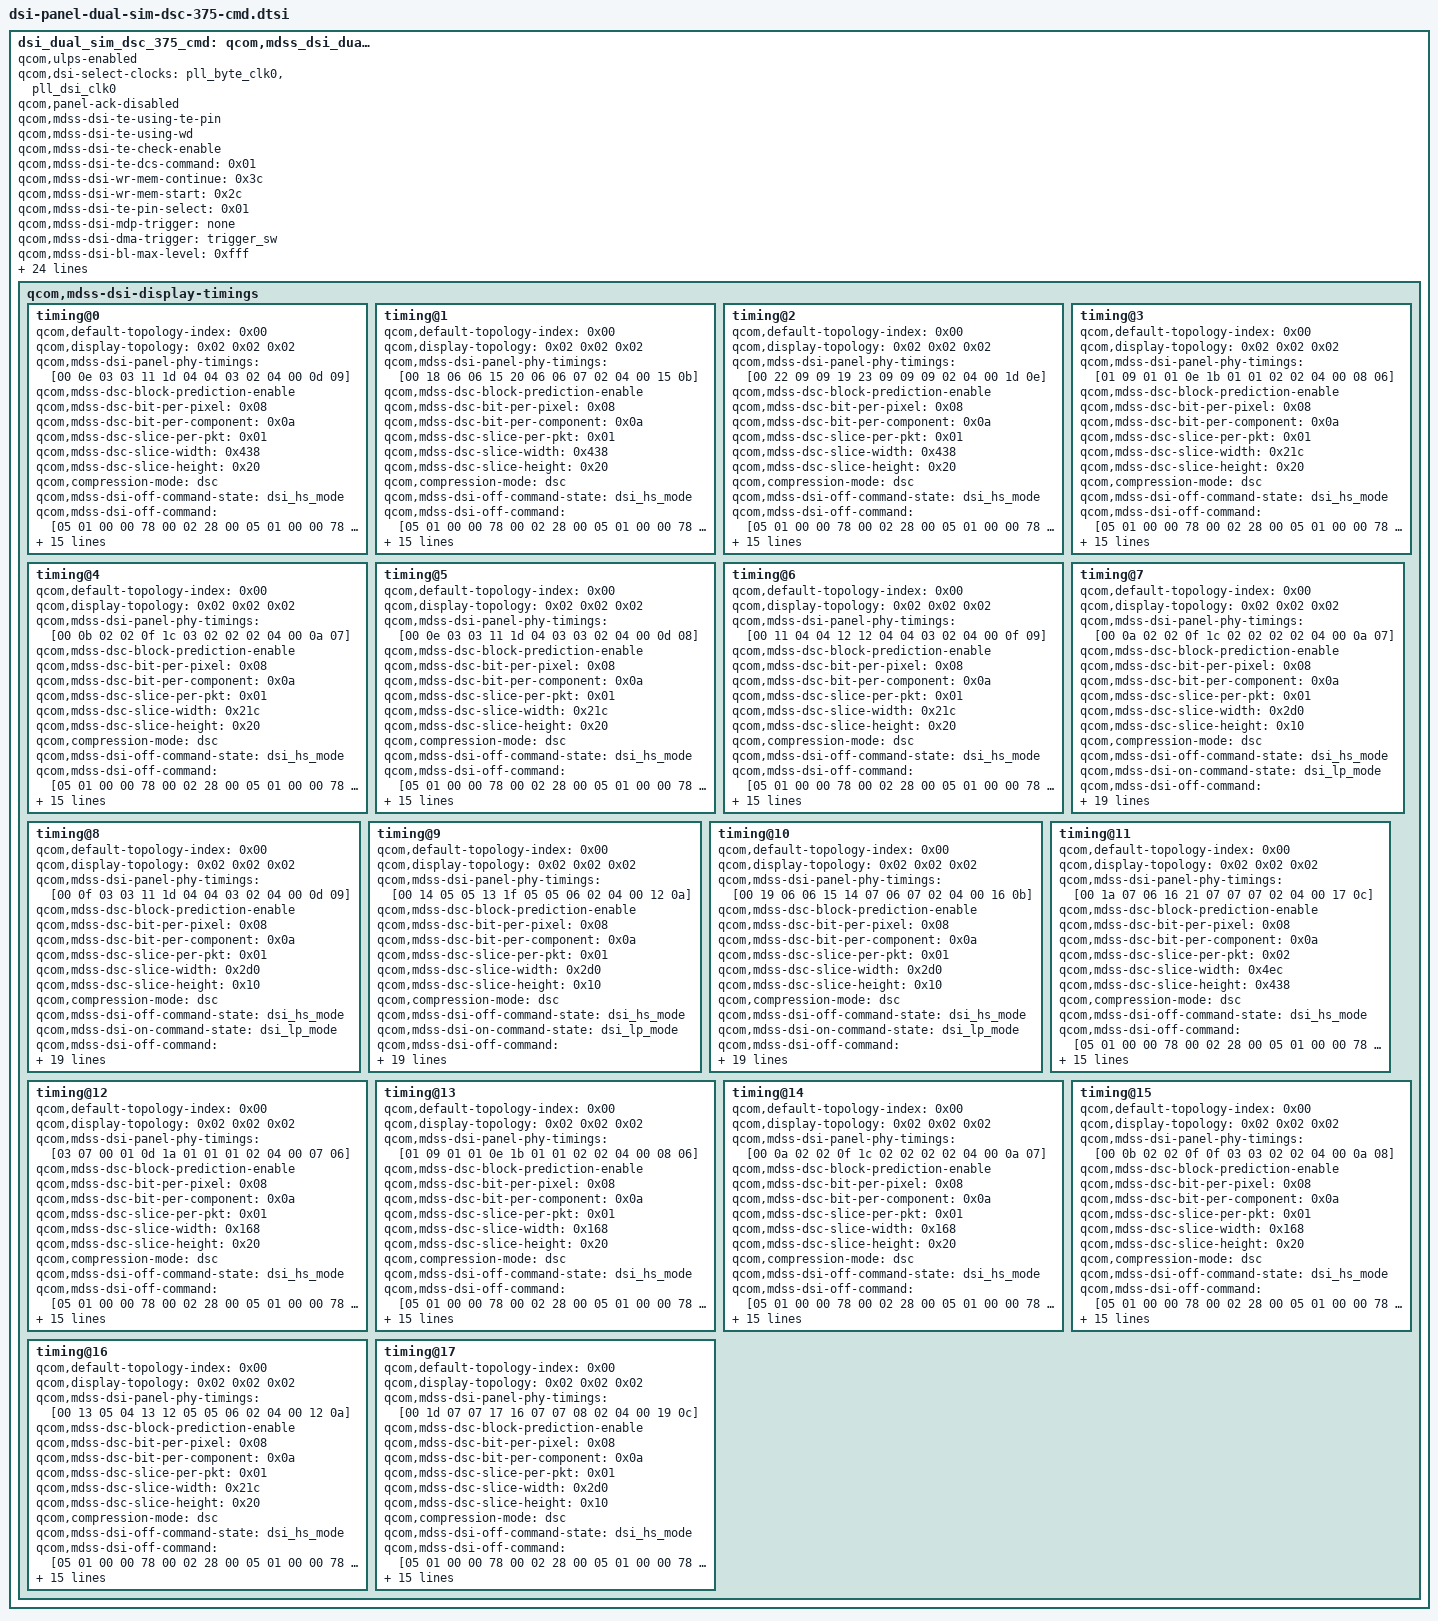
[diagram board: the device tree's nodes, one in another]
// SPDX-License-Identifier: BSD-3-Clause
/*
 * Copyright (c) 2023-2024 Qualcomm Innovation Center, Inc. All rights reserved.
 * Copyright (c) 2025 The LineageOS Project
 */

dsi_dual_sim_dsc_375_cmd: qcom,mdss_dsi_dual_sim_dsc_375_cmd {
	qcom,ulps-enabled;
	qcom,dsi-select-clocks = "pll_byte_clk0", "pll_dsi_clk0";
	qcom,panel-ack-disabled;
	qcom,mdss-dsi-te-using-te-pin;
	qcom,mdss-dsi-te-using-wd;
	qcom,mdss-dsi-te-check-enable;
	qcom,mdss-dsi-te-dcs-command = <0x01>;
	qcom,mdss-dsi-wr-mem-continue = <0x3c>;
	qcom,mdss-dsi-wr-mem-start = <0x2c>;
	qcom,mdss-dsi-te-pin-select = <0x01>;
	qcom,mdss-dsi-mdp-trigger = "none";
	qcom,mdss-dsi-dma-trigger = "trigger_sw";
	qcom,mdss-dsi-bl-max-level = <0xfff>;
	qcom,mdss-dsi-reset-sequence = <0x01 0x0a 0x00 0x0a 0x01 0x0a>;
	qcom,mdss-dsi-hor-line-idle = <0x00 0x28 0x100 0x28 0x78 0x80 0x78 0xf0 0x40>;
	qcom,mdss-dsi-lane-3-state;
	qcom,mdss-dsi-lane-2-state;
	qcom,mdss-dsi-lane-1-state;
	qcom,mdss-dsi-lane-0-state;
	qcom,cmd-sync-wait-broadcast;
	qcom,mdss-dsi-bllp-power-mode;
	qcom,mdss-dsi-bllp-eof-power-mode;
	qcom,mdss-dsi-traffic-mode = "non_burst_sync_event";
	qcom,mdss-dsi-border-color = <0x00>;
	qcom,mdss-dsi-underflow-color = <0xff>;
	qcom,mdss-dsi-color-order = "rgb_swap_rgb";
	qcom,mdss-dsi-bpp = <0x18>;
	qcom,mdss-dsi-stream = <0x00>;
	qcom,mdss-dsi-virtual-channel-id = <0x00>;
	qcom,dsi-phy-num = <0x00 0x01>;
	qcom,dsi-ctrl-num = <0x00 0x01>;
	qcom,mdss-dsi-panel-type = "dsi_cmd_mode";
	qcom,mdss-dsi-panel-name = "Sim dual cmd mode DSC 3.75:1 dsi panel";

	qcom,mdss-dsi-display-timings {

		timing@0 {
			qcom,default-topology-index = <0x00>;
			qcom,display-topology = <0x02 0x02 0x02>;
			qcom,mdss-dsi-panel-phy-timings = [00 0e 03 03 11 1d 04 04 03 02 04 00 0d 09];
			qcom,mdss-dsc-block-prediction-enable;
			qcom,mdss-dsc-bit-per-pixel = <0x08>;
			qcom,mdss-dsc-bit-per-component = <0x0a>;
			qcom,mdss-dsc-slice-per-pkt = <0x01>;
			qcom,mdss-dsc-slice-width = <0x438>;
			qcom,mdss-dsc-slice-height = <0x20>;
			qcom,compression-mode = "dsc";
			qcom,mdss-dsi-off-command-state = "dsi_hs_mode";
			qcom,mdss-dsi-off-command = [05 01 00 00 78 00 02 28 00 05 01 00 00 78 00 02 10 00];
			qcom,mdss-dsi-on-command-state = "dsi_lp_mode";
			qcom,mdss-dsi-on-command = [39 01 00 00 00 00 11 91 09 20 00 20 02 00 03 1c 04 21 00 0f 03 19 01 97 39 01 00 00 00 00 03 92 10 f0 15 01 00 00 00 00 02 90 03 15 01 00 00 00 00 02 03 01 39 01 00 00 00 00 06 f0 55 aa 52 08 04 15 01 00 00 00 00 02 c0 03 39 01 00 00 00 00 06 f0 55 aa 52 08 07 15 01 00 00 00 00 02 ef 01 39 01 00 00 00 00 06 f0 55 aa 52 08 00 15 01 00 00 00 00 02 b4 01 15 01 00 00 00 00 02 35 00 39 01 00 00 00 00 06 f0 55 aa 52 08 01 39 01 00 00 00 00 05 ff aa 55 a5 80 15 01 00 00 00 00 02 6f 01 15 01 00 00 00 00 02 f3 10 39 01 00 00 00 00 05 ff aa 55 a5 00 05 01 00 00 f0 00 01 00];
			qcom,mdss-dsi-panel-framerate = <0x1e>;
			qcom,mdss-dsi-h-sync-pulse = <0x00>;
			qcom,mdss-dsi-v-pulse-width = <0x01>;
			qcom,mdss-dsi-v-front-porch = <0x08>;
			qcom,mdss-dsi-v-back-porch = <0x07>;
			qcom,mdss-dsi-h-sync-skew = <0x00>;
			qcom,mdss-dsi-h-pulse-width = <0x04>;
			qcom,mdss-dsi-h-back-porch = <0x64>;
			qcom,mdss-dsi-h-front-porch = <0x1e>;
			qcom,mdss-dsi-panel-height = <0xf00>;
			qcom,mdss-dsi-panel-width = <0x438>;
			cell-index = <0x00>;
		};

		timing@1 {
			qcom,default-topology-index = <0x00>;
			qcom,display-topology = <0x02 0x02 0x02>;
			qcom,mdss-dsi-panel-phy-timings = [00 18 06 06 15 20 06 06 07 02 04 00 15 0b];
			qcom,mdss-dsc-block-prediction-enable;
			qcom,mdss-dsc-bit-per-pixel = <0x08>;
			qcom,mdss-dsc-bit-per-component = <0x0a>;
			qcom,mdss-dsc-slice-per-pkt = <0x01>;
			qcom,mdss-dsc-slice-width = <0x438>;
			qcom,mdss-dsc-slice-height = <0x20>;
			qcom,compression-mode = "dsc";
			qcom,mdss-dsi-off-command-state = "dsi_hs_mode";
			qcom,mdss-dsi-off-command = [05 01 00 00 78 00 02 28 00 05 01 00 00 78 00 02 10 00];
			qcom,mdss-dsi-on-command-state = "dsi_lp_mode";
			qcom,mdss-dsi-on-command = [39 01 00 00 00 00 11 91 09 20 00 20 02 00 03 1c 04 21 00 0f 03 19 01 97 39 01 00 00 00 00 03 92 10 f0 15 01 00 00 00 00 02 90 03 15 01 00 00 00 00 02 03 01 39 01 00 00 00 00 06 f0 55 aa 52 08 04 15 01 00 00 00 00 02 c0 03 39 01 00 00 00 00 06 f0 55 aa 52 08 07 15 01 00 00 00 00 02 ef 01 39 01 00 00 00 00 06 f0 55 aa 52 08 00 15 01 00 00 00 00 02 b4 01 15 01 00 00 00 00 02 35 00 39 01 00 00 00 00 06 f0 55 aa 52 08 01 39 01 00 00 00 00 05 ff aa 55 a5 80 15 01 00 00 00 00 02 6f 01 15 01 00 00 00 00 02 f3 10 39 01 00 00 00 00 05 ff aa 55 a5 00 05 01 00 00 f0 00 01 00];
			qcom,mdss-dsi-panel-framerate = <0x3c>;
			qcom,mdss-dsi-h-sync-pulse = <0x00>;
			qcom,mdss-dsi-v-pulse-width = <0x01>;
			qcom,mdss-dsi-v-front-porch = <0x08>;
			qcom,mdss-dsi-v-back-porch = <0x07>;
			qcom,mdss-dsi-h-sync-skew = <0x00>;
			qcom,mdss-dsi-h-pulse-width = <0x04>;
			qcom,mdss-dsi-h-back-porch = <0x64>;
			qcom,mdss-dsi-h-front-porch = <0x1e>;
			qcom,mdss-dsi-panel-height = <0xf00>;
			qcom,mdss-dsi-panel-width = <0x438>;
			cell-index = <0x01>;
		};

		timing@2 {
			qcom,default-topology-index = <0x00>;
			qcom,display-topology = <0x02 0x02 0x02>;
			qcom,mdss-dsi-panel-phy-timings = [00 22 09 09 19 23 09 09 09 02 04 00 1d 0e];
			qcom,mdss-dsc-block-prediction-enable;
			qcom,mdss-dsc-bit-per-pixel = <0x08>;
			qcom,mdss-dsc-bit-per-component = <0x0a>;
			qcom,mdss-dsc-slice-per-pkt = <0x01>;
			qcom,mdss-dsc-slice-width = <0x438>;
			qcom,mdss-dsc-slice-height = <0x20>;
			qcom,compression-mode = "dsc";
			qcom,mdss-dsi-off-command-state = "dsi_hs_mode";
			qcom,mdss-dsi-off-command = [05 01 00 00 78 00 02 28 00 05 01 00 00 78 00 02 10 00];
			qcom,mdss-dsi-on-command-state = "dsi_lp_mode";
			qcom,mdss-dsi-on-command = [39 01 00 00 00 00 11 91 09 20 00 20 02 00 03 1c 04 21 00 0f 03 19 01 97 39 01 00 00 00 00 03 92 10 f0 15 01 00 00 00 00 02 90 03 15 01 00 00 00 00 02 03 01 39 01 00 00 00 00 06 f0 55 aa 52 08 04 15 01 00 00 00 00 02 c0 03 39 01 00 00 00 00 06 f0 55 aa 52 08 07 15 01 00 00 00 00 02 ef 01 39 01 00 00 00 00 06 f0 55 aa 52 08 00 15 01 00 00 00 00 02 b4 01 15 01 00 00 00 00 02 35 00 39 01 00 00 00 00 06 f0 55 aa 52 08 01 39 01 00 00 00 00 05 ff aa 55 a5 80 15 01 00 00 00 00 02 6f 01 15 01 00 00 00 00 02 f3 10 39 01 00 00 00 00 05 ff aa 55 a5 00 05 01 00 00 f0 00 01 00];
			qcom,mdss-dsi-panel-framerate = <0x5a>;
			qcom,mdss-dsi-h-sync-pulse = <0x00>;
			qcom,mdss-dsi-v-pulse-width = <0x01>;
			qcom,mdss-dsi-v-front-porch = <0x08>;
			qcom,mdss-dsi-v-back-porch = <0x07>;
			qcom,mdss-dsi-h-sync-skew = <0x00>;
			qcom,mdss-dsi-h-pulse-width = <0x04>;
			qcom,mdss-dsi-h-back-porch = <0x64>;
			qcom,mdss-dsi-h-front-porch = <0x1e>;
			qcom,mdss-dsi-panel-height = <0xf00>;
			qcom,mdss-dsi-panel-width = <0x438>;
			cell-index = <0x02>;
		};

		timing@3 {
			qcom,default-topology-index = <0x00>;
			qcom,display-topology = <0x02 0x02 0x02>;
			qcom,mdss-dsi-panel-phy-timings = [01 09 01 01 0e 1b 01 01 02 02 04 00 08 06];
			qcom,mdss-dsc-block-prediction-enable;
			qcom,mdss-dsc-bit-per-pixel = <0x08>;
			qcom,mdss-dsc-bit-per-component = <0x0a>;
			qcom,mdss-dsc-slice-per-pkt = <0x01>;
			qcom,mdss-dsc-slice-width = <0x21c>;
			qcom,mdss-dsc-slice-height = <0x20>;
			qcom,compression-mode = "dsc";
			qcom,mdss-dsi-off-command-state = "dsi_hs_mode";
			qcom,mdss-dsi-off-command = [05 01 00 00 78 00 02 28 00 05 01 00 00 78 00 02 10 00];
			qcom,mdss-dsi-on-command-state = "dsi_lp_mode";
			qcom,mdss-dsi-on-command = [39 01 00 00 00 00 11 91 09 20 00 20 02 00 03 1c 04 21 00 0f 03 19 01 97 39 01 00 00 00 00 03 92 10 f0 15 01 00 00 00 00 02 90 03 15 01 00 00 00 00 02 03 01 39 01 00 00 00 00 06 f0 55 aa 52 08 04 15 01 00 00 00 00 02 c0 03 39 01 00 00 00 00 06 f0 55 aa 52 08 07 15 01 00 00 00 00 02 ef 01 39 01 00 00 00 00 06 f0 55 aa 52 08 00 15 01 00 00 00 00 02 b4 01 15 01 00 00 00 00 02 35 00 39 01 00 00 00 00 06 f0 55 aa 52 08 01 39 01 00 00 00 00 05 ff aa 55 a5 80 15 01 00 00 00 00 02 6f 01 15 01 00 00 00 00 02 f3 10 39 01 00 00 00 00 05 ff aa 55 a5 00 05 01 00 00 f0 00 01 00];
			qcom,mdss-dsi-panel-framerate = <0x1e>;
			qcom,mdss-dsi-h-sync-pulse = <0x00>;
			qcom,mdss-dsi-v-pulse-width = <0x01>;
			qcom,mdss-dsi-v-front-porch = <0x08>;
			qcom,mdss-dsi-v-back-porch = <0x07>;
			qcom,mdss-dsi-h-sync-skew = <0x00>;
			qcom,mdss-dsi-h-pulse-width = <0x04>;
			qcom,mdss-dsi-h-back-porch = <0x64>;
			qcom,mdss-dsi-h-front-porch = <0x1e>;
			qcom,mdss-dsi-panel-height = <0x780>;
			qcom,mdss-dsi-panel-width = <0x21c>;
			cell-index = <0x04>;
		};

		timing@4 {
			qcom,default-topology-index = <0x00>;
			qcom,display-topology = <0x02 0x02 0x02>;
			qcom,mdss-dsi-panel-phy-timings = [00 0b 02 02 0f 1c 03 02 02 02 04 00 0a 07];
			qcom,mdss-dsc-block-prediction-enable;
			qcom,mdss-dsc-bit-per-pixel = <0x08>;
			qcom,mdss-dsc-bit-per-component = <0x0a>;
			qcom,mdss-dsc-slice-per-pkt = <0x01>;
			qcom,mdss-dsc-slice-width = <0x21c>;
			qcom,mdss-dsc-slice-height = <0x20>;
			qcom,compression-mode = "dsc";
			qcom,mdss-dsi-off-command-state = "dsi_hs_mode";
			qcom,mdss-dsi-off-command = [05 01 00 00 78 00 02 28 00 05 01 00 00 78 00 02 10 00];
			qcom,mdss-dsi-on-command-state = "dsi_lp_mode";
			qcom,mdss-dsi-on-command = [39 01 00 00 00 00 11 91 09 20 00 20 02 00 03 1c 04 21 00 0f 03 19 01 97 39 01 00 00 00 00 03 92 10 f0 15 01 00 00 00 00 02 90 03 15 01 00 00 00 00 02 03 01 39 01 00 00 00 00 06 f0 55 aa 52 08 04 15 01 00 00 00 00 02 c0 03 39 01 00 00 00 00 06 f0 55 aa 52 08 07 15 01 00 00 00 00 02 ef 01 39 01 00 00 00 00 06 f0 55 aa 52 08 00 15 01 00 00 00 00 02 b4 01 15 01 00 00 00 00 02 35 00 39 01 00 00 00 00 06 f0 55 aa 52 08 01 39 01 00 00 00 00 05 ff aa 55 a5 80 15 01 00 00 00 00 02 6f 01 15 01 00 00 00 00 02 f3 10 39 01 00 00 00 00 05 ff aa 55 a5 00 05 01 00 00 f0 00 01 00];
			qcom,mdss-dsi-panel-framerate = <0x3c>;
			qcom,mdss-dsi-h-sync-pulse = <0x00>;
			qcom,mdss-dsi-v-pulse-width = <0x01>;
			qcom,mdss-dsi-v-front-porch = <0x08>;
			qcom,mdss-dsi-v-back-porch = <0x07>;
			qcom,mdss-dsi-h-sync-skew = <0x00>;
			qcom,mdss-dsi-h-pulse-width = <0x04>;
			qcom,mdss-dsi-h-back-porch = <0x64>;
			qcom,mdss-dsi-h-front-porch = <0x1e>;
			qcom,mdss-dsi-panel-height = <0x780>;
			qcom,mdss-dsi-panel-width = <0x21c>;
			cell-index = <0x05>;
		};

		timing@5 {
			qcom,default-topology-index = <0x00>;
			qcom,display-topology = <0x02 0x02 0x02>;
			qcom,mdss-dsi-panel-phy-timings = [00 0e 03 03 11 1d 04 03 03 02 04 00 0d 08];
			qcom,mdss-dsc-block-prediction-enable;
			qcom,mdss-dsc-bit-per-pixel = <0x08>;
			qcom,mdss-dsc-bit-per-component = <0x0a>;
			qcom,mdss-dsc-slice-per-pkt = <0x01>;
			qcom,mdss-dsc-slice-width = <0x21c>;
			qcom,mdss-dsc-slice-height = <0x20>;
			qcom,compression-mode = "dsc";
			qcom,mdss-dsi-off-command-state = "dsi_hs_mode";
			qcom,mdss-dsi-off-command = [05 01 00 00 78 00 02 28 00 05 01 00 00 78 00 02 10 00];
			qcom,mdss-dsi-on-command-state = "dsi_lp_mode";
			qcom,mdss-dsi-on-command = [39 01 00 00 00 00 11 91 09 20 00 20 02 00 03 1c 04 21 00 0f 03 19 01 97 39 01 00 00 00 00 03 92 10 f0 15 01 00 00 00 00 02 90 03 15 01 00 00 00 00 02 03 01 39 01 00 00 00 00 06 f0 55 aa 52 08 04 15 01 00 00 00 00 02 c0 03 39 01 00 00 00 00 06 f0 55 aa 52 08 07 15 01 00 00 00 00 02 ef 01 39 01 00 00 00 00 06 f0 55 aa 52 08 00 15 01 00 00 00 00 02 b4 01 15 01 00 00 00 00 02 35 00 39 01 00 00 00 00 06 f0 55 aa 52 08 01 39 01 00 00 00 00 05 ff aa 55 a5 80 15 01 00 00 00 00 02 6f 01 15 01 00 00 00 00 02 f3 10 39 01 00 00 00 00 05 ff aa 55 a5 00 05 01 00 00 f0 00 01 00];
			qcom,mdss-dsi-panel-framerate = <0x5a>;
			qcom,mdss-dsi-h-sync-pulse = <0x00>;
			qcom,mdss-dsi-v-pulse-width = <0x01>;
			qcom,mdss-dsi-v-front-porch = <0x08>;
			qcom,mdss-dsi-v-back-porch = <0x07>;
			qcom,mdss-dsi-h-sync-skew = <0x00>;
			qcom,mdss-dsi-h-pulse-width = <0x04>;
			qcom,mdss-dsi-h-back-porch = <0x64>;
			qcom,mdss-dsi-h-front-porch = <0x1e>;
			qcom,mdss-dsi-panel-height = <0x780>;
			qcom,mdss-dsi-panel-width = <0x21c>;
			cell-index = <0x06>;
		};

		timing@6 {
			qcom,default-topology-index = <0x00>;
			qcom,display-topology = <0x02 0x02 0x02>;
			qcom,mdss-dsi-panel-phy-timings = [00 11 04 04 12 12 04 04 03 02 04 00 0f 09];
			qcom,mdss-dsc-block-prediction-enable;
			qcom,mdss-dsc-bit-per-pixel = <0x08>;
			qcom,mdss-dsc-bit-per-component = <0x0a>;
			qcom,mdss-dsc-slice-per-pkt = <0x01>;
			qcom,mdss-dsc-slice-width = <0x21c>;
			qcom,mdss-dsc-slice-height = <0x20>;
			qcom,compression-mode = "dsc";
			qcom,mdss-dsi-off-command-state = "dsi_hs_mode";
			qcom,mdss-dsi-off-command = [05 01 00 00 78 00 02 28 00 05 01 00 00 78 00 02 10 00];
			qcom,mdss-dsi-on-command-state = "dsi_lp_mode";
			qcom,mdss-dsi-on-command = [39 01 00 00 00 00 11 91 09 20 00 20 02 00 03 1c 04 21 00 0f 03 19 01 97 39 01 00 00 00 00 03 92 10 f0 15 01 00 00 00 00 02 90 03 15 01 00 00 00 00 02 03 01 39 01 00 00 00 00 06 f0 55 aa 52 08 04 15 01 00 00 00 00 02 c0 03 39 01 00 00 00 00 06 f0 55 aa 52 08 07 15 01 00 00 00 00 02 ef 01 39 01 00 00 00 00 06 f0 55 aa 52 08 00 15 01 00 00 00 00 02 b4 01 15 01 00 00 00 00 02 35 00 39 01 00 00 00 00 06 f0 55 aa 52 08 01 39 01 00 00 00 00 05 ff aa 55 a5 80 15 01 00 00 00 00 02 6f 01 15 01 00 00 00 00 02 f3 10 39 01 00 00 00 00 05 ff aa 55 a5 00 05 01 00 00 f0 00 01 00];
			qcom,mdss-dsi-panel-framerate = <0x78>;
			qcom,mdss-dsi-h-sync-pulse = <0x00>;
			qcom,mdss-dsi-v-pulse-width = <0x01>;
			qcom,mdss-dsi-v-front-porch = <0x08>;
			qcom,mdss-dsi-v-back-porch = <0x07>;
			qcom,mdss-dsi-h-sync-skew = <0x00>;
			qcom,mdss-dsi-h-pulse-width = <0x04>;
			qcom,mdss-dsi-h-back-porch = <0x64>;
			qcom,mdss-dsi-h-front-porch = <0x1e>;
			qcom,mdss-dsi-panel-height = <0x780>;
			qcom,mdss-dsi-panel-width = <0x21c>;
			cell-index = <0x07>;
		};

		timing@7 {
			qcom,default-topology-index = <0x00>;
			qcom,display-topology = <0x02 0x02 0x02>;
			qcom,mdss-dsi-panel-phy-timings = [00 0a 02 02 0f 1c 02 02 02 02 04 00 0a 07];
			qcom,mdss-dsc-block-prediction-enable;
			qcom,mdss-dsc-bit-per-pixel = <0x08>;
			qcom,mdss-dsc-bit-per-component = <0x0a>;
			qcom,mdss-dsc-slice-per-pkt = <0x01>;
			qcom,mdss-dsc-slice-width = <0x2d0>;
			qcom,mdss-dsc-slice-height = <0x10>;
			qcom,compression-mode = "dsc";
			qcom,mdss-dsi-off-command-state = "dsi_hs_mode";
			qcom,mdss-dsi-on-command-state = "dsi_lp_mode";
			qcom,mdss-dsi-off-command = [05 01 00 00 78 00 02 28 00 05 01 00 00 78 00 02 10 00];
			qcom,mdss-dsi-on-command = [15 01 00 00 00 00 02 ff 20 15 01 00 00 00 00 02 fb 01 15 01 00 00 00 00 02 00 01 15 01 00 00 00 00 02 01 55 15 01 00 00 00 00 02 02 45 15 01 00 00 00 00 02 05 40 15 01 00 00 00 00 02 06 19 15 01 00 00 00 00 02 07 1e 15 01 00 00 00 00 02 0b 73 15 01 00 00 00 00 02 0c 73 15 01 00 00 00 00 02 0e b0 15 01 00 00 00 00 02 0f ae 15 01 00 00 00 00 02 11 b8 15 01 00 00 00 00 02 13 00 15 01 00 00 00 00 02 58 80 15 01 00 00 00 00 02 59 01 15 01 00 00 00 00 02 5a 00 15 01 00 00 00 00 02 5b 01 15 01 00 00 00 00 02 5c 80 15 01 00 00 00 00 02 5d 81 15 01 00 00 00 00 02 5e 00 15 01 00 00 00 00 02 5f 01 15 01 00 00 00 00 02 72 31 15 01 00 00 00 00 02 68 03 15 01 00 00 00 00 02 ff 24 15 01 00 00 00 00 02 fb 01 15 01 00 00 00 00 02 00 1c 15 01 00 00 00 00 02 01 0b 15 01 00 00 00 00 02 02 0c 15 01 00 00 00 00 02 03 01 15 01 00 00 00 00 02 04 0f 15 01 00 00 00 00 02 05 10 15 01 00 00 00 00 02 06 10 15 01 00 00 00 00 02 07 10 15 01 00 00 00 00 02 08 89 15 01 00 00 00 00 02 09 8a 15 01 00 00 00 00 02 0a 13 15 01 00 00 00 00 02 0b 13 15 01 00 00 00 00 02 0c 15 15 01 00 00 00 00 02 0d 15 15 01 00 00 00 00 02 0e 17 15 01 00 00 00 00 02 0f 17 15 01 00 00 00 00 02 10 1c 15 01 00 00 00 00 02 11 0b 15 01 00 00 00 00 02 12 0c 15 01 00 00 00 00 02 13 01 15 01 00 00 00 00 02 14 0f 15 01 00 00 00 00 02 15 10 15 01 00 00 00 00 02 16 10 15 01 00 00 00 00 02 17 10 15 01 00 00 00 00 02 18 89 15 01 00 00 00 00 02 19 8a 15 01 00 00 00 00 02 1a 13 15 01 00 00 00 00 02 1b 13 15 01 00 00 00 00 02 1c 15 15 01 00 00 00 00 02 1d 15 15 01 00 00 00 00 02 1e 17 15 01 00 00 00 00 02 1f 17 15 01 00 00 00 00 02 20 40 15 01 00 00 00 00 02 21 01 15 01 00 00 00 00 02 22 00 15 01 00 00 00 00 02 23 40 15 01 00 00 00 00 02 24 40 15 01 00 00 00 00 02 25 6d 15 01 00 00 00 00 02 26 40 15 01 00 00 00 00 02 27 40 15 01 00 00 00 00 02 e0 00 15 01 00 00 00 00 02 dc 21 15 01 00 00 00 00 02 dd 22 15 01 00 00 00 00 02 de 07 15 01 00 00 00 00 02 df 07 15 01 00 00 00 00 02 e3 6d 15 01 00 00 00 00 02 e1 07 15 01 00 00 00 00 02 e2 07 15 01 00 00 00 00 02 29 d8 15 01 00 00 00 00 02 2a 2a 15 01 00 00 00 00 02 4b 03 15 01 00 00 00 00 02 4c 11 15 01 00 00 00 00 02 4d 10 15 01 00 00 00 00 02 4e 01 15 01 00 00 00 00 02 4f 01 15 01 00 00 00 00 02 50 10 15 01 00 00 00 00 02 51 00 15 01 00 00 00 00 02 52 80 15 01 00 00 00 00 02 53 00 15 01 00 00 00 00 02 56 00 15 01 00 00 00 00 02 54 07 15 01 00 00 00 00 02 58 07 15 01 00 00 00 00 02 55 25 15 01 00 00 00 00 02 5b 43 15 01 00 00 00 00 02 5c 00 15 01 00 00 00 00 02 5f 73 15 01 00 00 00 00 02 60 73 15 01 00 00 00 00 02 63 22 15 01 00 00 00 00 02 64 00 15 01 00 00 00 00 02 67 08 15 01 00 00 00 00 02 68 04 15 01 00 00 00 00 02 72 02 15 01 00 00 00 00 02 7a 80 15 01 00 00 00 00 02 7b 91 15 01 00 00 00 00 02 7c d8 15 01 00 00 00 00 02 7d 60 15 01 00 00 00 00 02 7f 15 15 01 00 00 00 00 02 75 15 15 01 00 00 00 00 02 b3 c0 15 01 00 00 00 00 02 b4 00 15 01 00 00 00 00 02 b5 00 15 01 00 00 00 00 02 78 00 15 01 00 00 00 00 02 79 00 15 01 00 00 00 00 02 80 00 15 01 00 00 00 00 02 83 00 15 01 00 00 00 00 02 93 0a 15 01 00 00 00 00 02 94 0a 15 01 00 00 00 00 02 8a 00 15 01 00 00 00 00 02 9b ff 15 01 00 00 00 00 02 9d b0 15 01 00 00 00 00 02 9f 63 15 01 00 00 00 00 02 98 10 15 01 00 00 00 00 02 ec 00 15 01 00 00 00 00 02 ff 10 39 01 00 00 00 00 04 3b 03 0a 0a 15 01 00 00 00 00 02 35 00 15 01 00 00 00 00 02 e5 01 15 01 00 00 00 00 02 bb 10 15 01 00 00 00 00 02 fb 01 05 01 00 00 f0 00 01 00];
			qcom,mdss-dsi-h-sync-pulse = <0x00>;
			qcom,mdss-dsi-v-bottom-border = <0x00>;
			qcom,mdss-dsi-v-top-border = <0x00>;
			qcom,mdss-dsi-h-right-border = <0x00>;
			qcom,mdss-dsi-h-left-border = <0x00>;
			qcom,mdss-dsi-v-pulse-width = <0x01>;
			qcom,mdss-dsi-v-front-porch = <0x08>;
			qcom,mdss-dsi-v-back-porch = <0x07>;
			qcom,mdss-dsi-h-sync-skew = <0x00>;
			qcom,mdss-dsi-h-pulse-width = <0x10>;
			qcom,mdss-dsi-h-back-porch = <0x20>;
			qcom,mdss-dsi-h-front-porch = <0x64>;
			qcom,mdss-dsi-panel-height = <0xa00>;
			qcom,mdss-dsi-panel-width = <0x2d0>;
			qcom,mdss-dsi-panel-framerate = <0x1e>;
			cell-index = <0x08>;
		};

		timing@8 {
			qcom,default-topology-index = <0x00>;
			qcom,display-topology = <0x02 0x02 0x02>;
			qcom,mdss-dsi-panel-phy-timings = [00 0f 03 03 11 1d 04 04 03 02 04 00 0d 09];
			qcom,mdss-dsc-block-prediction-enable;
			qcom,mdss-dsc-bit-per-pixel = <0x08>;
			qcom,mdss-dsc-bit-per-component = <0x0a>;
			qcom,mdss-dsc-slice-per-pkt = <0x01>;
			qcom,mdss-dsc-slice-width = <0x2d0>;
			qcom,mdss-dsc-slice-height = <0x10>;
			qcom,compression-mode = "dsc";
			qcom,mdss-dsi-off-command-state = "dsi_hs_mode";
			qcom,mdss-dsi-on-command-state = "dsi_lp_mode";
			qcom,mdss-dsi-off-command = [05 01 00 00 78 00 02 28 00 05 01 00 00 78 00 02 10 00];
			qcom,mdss-dsi-on-command = [15 01 00 00 00 00 02 ff 20 15 01 00 00 00 00 02 fb 01 15 01 00 00 00 00 02 00 01 15 01 00 00 00 00 02 01 55 15 01 00 00 00 00 02 02 45 15 01 00 00 00 00 02 05 40 15 01 00 00 00 00 02 06 19 15 01 00 00 00 00 02 07 1e 15 01 00 00 00 00 02 0b 73 15 01 00 00 00 00 02 0c 73 15 01 00 00 00 00 02 0e b0 15 01 00 00 00 00 02 0f ae 15 01 00 00 00 00 02 11 b8 15 01 00 00 00 00 02 13 00 15 01 00 00 00 00 02 58 80 15 01 00 00 00 00 02 59 01 15 01 00 00 00 00 02 5a 00 15 01 00 00 00 00 02 5b 01 15 01 00 00 00 00 02 5c 80 15 01 00 00 00 00 02 5d 81 15 01 00 00 00 00 02 5e 00 15 01 00 00 00 00 02 5f 01 15 01 00 00 00 00 02 72 31 15 01 00 00 00 00 02 68 03 15 01 00 00 00 00 02 ff 24 15 01 00 00 00 00 02 fb 01 15 01 00 00 00 00 02 00 1c 15 01 00 00 00 00 02 01 0b 15 01 00 00 00 00 02 02 0c 15 01 00 00 00 00 02 03 01 15 01 00 00 00 00 02 04 0f 15 01 00 00 00 00 02 05 10 15 01 00 00 00 00 02 06 10 15 01 00 00 00 00 02 07 10 15 01 00 00 00 00 02 08 89 15 01 00 00 00 00 02 09 8a 15 01 00 00 00 00 02 0a 13 15 01 00 00 00 00 02 0b 13 15 01 00 00 00 00 02 0c 15 15 01 00 00 00 00 02 0d 15 15 01 00 00 00 00 02 0e 17 15 01 00 00 00 00 02 0f 17 15 01 00 00 00 00 02 10 1c 15 01 00 00 00 00 02 11 0b 15 01 00 00 00 00 02 12 0c 15 01 00 00 00 00 02 13 01 15 01 00 00 00 00 02 14 0f 15 01 00 00 00 00 02 15 10 15 01 00 00 00 00 02 16 10 15 01 00 00 00 00 02 17 10 15 01 00 00 00 00 02 18 89 15 01 00 00 00 00 02 19 8a 15 01 00 00 00 00 02 1a 13 15 01 00 00 00 00 02 1b 13 15 01 00 00 00 00 02 1c 15 15 01 00 00 00 00 02 1d 15 15 01 00 00 00 00 02 1e 17 15 01 00 00 00 00 02 1f 17 15 01 00 00 00 00 02 20 40 15 01 00 00 00 00 02 21 01 15 01 00 00 00 00 02 22 00 15 01 00 00 00 00 02 23 40 15 01 00 00 00 00 02 24 40 15 01 00 00 00 00 02 25 6d 15 01 00 00 00 00 02 26 40 15 01 00 00 00 00 02 27 40 15 01 00 00 00 00 02 e0 00 15 01 00 00 00 00 02 dc 21 15 01 00 00 00 00 02 dd 22 15 01 00 00 00 00 02 de 07 15 01 00 00 00 00 02 df 07 15 01 00 00 00 00 02 e3 6d 15 01 00 00 00 00 02 e1 07 15 01 00 00 00 00 02 e2 07 15 01 00 00 00 00 02 29 d8 15 01 00 00 00 00 02 2a 2a 15 01 00 00 00 00 02 4b 03 15 01 00 00 00 00 02 4c 11 15 01 00 00 00 00 02 4d 10 15 01 00 00 00 00 02 4e 01 15 01 00 00 00 00 02 4f 01 15 01 00 00 00 00 02 50 10 15 01 00 00 00 00 02 51 00 15 01 00 00 00 00 02 52 80 15 01 00 00 00 00 02 53 00 15 01 00 00 00 00 02 56 00 15 01 00 00 00 00 02 54 07 15 01 00 00 00 00 02 58 07 15 01 00 00 00 00 02 55 25 15 01 00 00 00 00 02 5b 43 15 01 00 00 00 00 02 5c 00 15 01 00 00 00 00 02 5f 73 15 01 00 00 00 00 02 60 73 15 01 00 00 00 00 02 63 22 15 01 00 00 00 00 02 64 00 15 01 00 00 00 00 02 67 08 15 01 00 00 00 00 02 68 04 15 01 00 00 00 00 02 72 02 15 01 00 00 00 00 02 7a 80 15 01 00 00 00 00 02 7b 91 15 01 00 00 00 00 02 7c d8 15 01 00 00 00 00 02 7d 60 15 01 00 00 00 00 02 7f 15 15 01 00 00 00 00 02 75 15 15 01 00 00 00 00 02 b3 c0 15 01 00 00 00 00 02 b4 00 15 01 00 00 00 00 02 b5 00 15 01 00 00 00 00 02 78 00 15 01 00 00 00 00 02 79 00 15 01 00 00 00 00 02 80 00 15 01 00 00 00 00 02 83 00 15 01 00 00 00 00 02 93 0a 15 01 00 00 00 00 02 94 0a 15 01 00 00 00 00 02 8a 00 15 01 00 00 00 00 02 9b ff 15 01 00 00 00 00 02 9d b0 15 01 00 00 00 00 02 9f 63 15 01 00 00 00 00 02 98 10 15 01 00 00 00 00 02 ec 00 15 01 00 00 00 00 02 ff 10 39 01 00 00 00 00 04 3b 03 0a 0a 15 01 00 00 00 00 02 35 00 15 01 00 00 00 00 02 e5 01 15 01 00 00 00 00 02 bb 10 15 01 00 00 00 00 02 fb 01 05 01 00 00 f0 00 01 00];
			qcom,mdss-dsi-h-sync-pulse = <0x00>;
			qcom,mdss-dsi-v-bottom-border = <0x00>;
			qcom,mdss-dsi-v-top-border = <0x00>;
			qcom,mdss-dsi-h-right-border = <0x00>;
			qcom,mdss-dsi-h-left-border = <0x00>;
			qcom,mdss-dsi-v-pulse-width = <0x01>;
			qcom,mdss-dsi-v-front-porch = <0x08>;
			qcom,mdss-dsi-v-back-porch = <0x07>;
			qcom,mdss-dsi-h-sync-skew = <0x00>;
			qcom,mdss-dsi-h-pulse-width = <0x10>;
			qcom,mdss-dsi-h-back-porch = <0x20>;
			qcom,mdss-dsi-h-front-porch = <0x64>;
			qcom,mdss-dsi-panel-height = <0xa00>;
			qcom,mdss-dsi-panel-width = <0x2d0>;
			qcom,mdss-dsi-panel-framerate = <0x3c>;
			cell-index = <0x09>;
		};

		timing@9 {
			qcom,default-topology-index = <0x00>;
			qcom,display-topology = <0x02 0x02 0x02>;
			qcom,mdss-dsi-panel-phy-timings = [00 14 05 05 13 1f 05 05 06 02 04 00 12 0a];
			qcom,mdss-dsc-block-prediction-enable;
			qcom,mdss-dsc-bit-per-pixel = <0x08>;
			qcom,mdss-dsc-bit-per-component = <0x0a>;
			qcom,mdss-dsc-slice-per-pkt = <0x01>;
			qcom,mdss-dsc-slice-width = <0x2d0>;
			qcom,mdss-dsc-slice-height = <0x10>;
			qcom,compression-mode = "dsc";
			qcom,mdss-dsi-off-command-state = "dsi_hs_mode";
			qcom,mdss-dsi-on-command-state = "dsi_lp_mode";
			qcom,mdss-dsi-off-command = [05 01 00 00 78 00 02 28 00 05 01 00 00 78 00 02 10 00];
			qcom,mdss-dsi-on-command = [15 01 00 00 00 00 02 ff 20 15 01 00 00 00 00 02 fb 01 15 01 00 00 00 00 02 00 01 15 01 00 00 00 00 02 01 55 15 01 00 00 00 00 02 02 45 15 01 00 00 00 00 02 05 40 15 01 00 00 00 00 02 06 19 15 01 00 00 00 00 02 07 1e 15 01 00 00 00 00 02 0b 73 15 01 00 00 00 00 02 0c 73 15 01 00 00 00 00 02 0e b0 15 01 00 00 00 00 02 0f ae 15 01 00 00 00 00 02 11 b8 15 01 00 00 00 00 02 13 00 15 01 00 00 00 00 02 58 80 15 01 00 00 00 00 02 59 01 15 01 00 00 00 00 02 5a 00 15 01 00 00 00 00 02 5b 01 15 01 00 00 00 00 02 5c 80 15 01 00 00 00 00 02 5d 81 15 01 00 00 00 00 02 5e 00 15 01 00 00 00 00 02 5f 01 15 01 00 00 00 00 02 72 31 15 01 00 00 00 00 02 68 03 15 01 00 00 00 00 02 ff 24 15 01 00 00 00 00 02 fb 01 15 01 00 00 00 00 02 00 1c 15 01 00 00 00 00 02 01 0b 15 01 00 00 00 00 02 02 0c 15 01 00 00 00 00 02 03 01 15 01 00 00 00 00 02 04 0f 15 01 00 00 00 00 02 05 10 15 01 00 00 00 00 02 06 10 15 01 00 00 00 00 02 07 10 15 01 00 00 00 00 02 08 89 15 01 00 00 00 00 02 09 8a 15 01 00 00 00 00 02 0a 13 15 01 00 00 00 00 02 0b 13 15 01 00 00 00 00 02 0c 15 15 01 00 00 00 00 02 0d 15 15 01 00 00 00 00 02 0e 17 15 01 00 00 00 00 02 0f 17 15 01 00 00 00 00 02 10 1c 15 01 00 00 00 00 02 11 0b 15 01 00 00 00 00 02 12 0c 15 01 00 00 00 00 02 13 01 15 01 00 00 00 00 02 14 0f 15 01 00 00 00 00 02 15 10 15 01 00 00 00 00 02 16 10 15 01 00 00 00 00 02 17 10 15 01 00 00 00 00 02 18 89 15 01 00 00 00 00 02 19 8a 15 01 00 00 00 00 02 1a 13 15 01 00 00 00 00 02 1b 13 15 01 00 00 00 00 02 1c 15 15 01 00 00 00 00 02 1d 15 15 01 00 00 00 00 02 1e 17 15 01 00 00 00 00 02 1f 17 15 01 00 00 00 00 02 20 40 15 01 00 00 00 00 02 21 01 15 01 00 00 00 00 02 22 00 15 01 00 00 00 00 02 23 40 15 01 00 00 00 00 02 24 40 15 01 00 00 00 00 02 25 6d 15 01 00 00 00 00 02 26 40 15 01 00 00 00 00 02 27 40 15 01 00 00 00 00 02 e0 00 15 01 00 00 00 00 02 dc 21 15 01 00 00 00 00 02 dd 22 15 01 00 00 00 00 02 de 07 15 01 00 00 00 00 02 df 07 15 01 00 00 00 00 02 e3 6d 15 01 00 00 00 00 02 e1 07 15 01 00 00 00 00 02 e2 07 15 01 00 00 00 00 02 29 d8 15 01 00 00 00 00 02 2a 2a 15 01 00 00 00 00 02 4b 03 15 01 00 00 00 00 02 4c 11 15 01 00 00 00 00 02 4d 10 15 01 00 00 00 00 02 4e 01 15 01 00 00 00 00 02 4f 01 15 01 00 00 00 00 02 50 10 15 01 00 00 00 00 02 51 00 15 01 00 00 00 00 02 52 80 15 01 00 00 00 00 02 53 00 15 01 00 00 00 00 02 56 00 15 01 00 00 00 00 02 54 07 15 01 00 00 00 00 02 58 07 15 01 00 00 00 00 02 55 25 15 01 00 00 00 00 02 5b 43 15 01 00 00 00 00 02 5c 00 15 01 00 00 00 00 02 5f 73 15 01 00 00 00 00 02 60 73 15 01 00 00 00 00 02 63 22 15 01 00 00 00 00 02 64 00 15 01 00 00 00 00 02 67 08 15 01 00 00 00 00 02 68 04 15 01 00 00 00 00 02 72 02 15 01 00 00 00 00 02 7a 80 15 01 00 00 00 00 02 7b 91 15 01 00 00 00 00 02 7c d8 15 01 00 00 00 00 02 7d 60 15 01 00 00 00 00 02 7f 15 15 01 00 00 00 00 02 75 15 15 01 00 00 00 00 02 b3 c0 15 01 00 00 00 00 02 b4 00 15 01 00 00 00 00 02 b5 00 15 01 00 00 00 00 02 78 00 15 01 00 00 00 00 02 79 00 15 01 00 00 00 00 02 80 00 15 01 00 00 00 00 02 83 00 15 01 00 00 00 00 02 93 0a 15 01 00 00 00 00 02 94 0a 15 01 00 00 00 00 02 8a 00 15 01 00 00 00 00 02 9b ff 15 01 00 00 00 00 02 9d b0 15 01 00 00 00 00 02 9f 63 15 01 00 00 00 00 02 98 10 15 01 00 00 00 00 02 ec 00 15 01 00 00 00 00 02 ff 10 39 01 00 00 00 00 04 3b 03 0a 0a 15 01 00 00 00 00 02 35 00 15 01 00 00 00 00 02 e5 01 15 01 00 00 00 00 02 bb 10 15 01 00 00 00 00 02 fb 01 05 01 00 00 f0 00 01 00];
			qcom,mdss-dsi-h-sync-pulse = <0x00>;
			qcom,mdss-dsi-v-bottom-border = <0x00>;
			qcom,mdss-dsi-v-top-border = <0x00>;
			qcom,mdss-dsi-h-right-border = <0x00>;
			qcom,mdss-dsi-h-left-border = <0x00>;
			qcom,mdss-dsi-v-pulse-width = <0x01>;
			qcom,mdss-dsi-v-front-porch = <0x08>;
			qcom,mdss-dsi-v-back-porch = <0x07>;
			qcom,mdss-dsi-h-sync-skew = <0x00>;
			qcom,mdss-dsi-h-pulse-width = <0x10>;
			qcom,mdss-dsi-h-back-porch = <0x20>;
			qcom,mdss-dsi-h-front-porch = <0x64>;
			qcom,mdss-dsi-panel-height = <0xa00>;
			qcom,mdss-dsi-panel-width = <0x2d0>;
			qcom,mdss-dsi-panel-framerate = <0x5a>;
			cell-index = <0x0a>;
		};

		timing@10 {
			qcom,default-topology-index = <0x00>;
			qcom,display-topology = <0x02 0x02 0x02>;
			qcom,mdss-dsi-panel-phy-timings = [00 19 06 06 15 14 07 06 07 02 04 00 16 0b];
			qcom,mdss-dsc-block-prediction-enable;
			qcom,mdss-dsc-bit-per-pixel = <0x08>;
			qcom,mdss-dsc-bit-per-component = <0x0a>;
			qcom,mdss-dsc-slice-per-pkt = <0x01>;
			qcom,mdss-dsc-slice-width = <0x2d0>;
			qcom,mdss-dsc-slice-height = <0x10>;
			qcom,compression-mode = "dsc";
			qcom,mdss-dsi-off-command-state = "dsi_hs_mode";
			qcom,mdss-dsi-on-command-state = "dsi_lp_mode";
			qcom,mdss-dsi-off-command = [05 01 00 00 78 00 02 28 00 05 01 00 00 78 00 02 10 00];
			qcom,mdss-dsi-on-command = [15 01 00 00 00 00 02 ff 20 15 01 00 00 00 00 02 fb 01 15 01 00 00 00 00 02 00 01 15 01 00 00 00 00 02 01 55 15 01 00 00 00 00 02 02 45 15 01 00 00 00 00 02 05 40 15 01 00 00 00 00 02 06 19 15 01 00 00 00 00 02 07 1e 15 01 00 00 00 00 02 0b 73 15 01 00 00 00 00 02 0c 73 15 01 00 00 00 00 02 0e b0 15 01 00 00 00 00 02 0f ae 15 01 00 00 00 00 02 11 b8 15 01 00 00 00 00 02 13 00 15 01 00 00 00 00 02 58 80 15 01 00 00 00 00 02 59 01 15 01 00 00 00 00 02 5a 00 15 01 00 00 00 00 02 5b 01 15 01 00 00 00 00 02 5c 80 15 01 00 00 00 00 02 5d 81 15 01 00 00 00 00 02 5e 00 15 01 00 00 00 00 02 5f 01 15 01 00 00 00 00 02 72 31 15 01 00 00 00 00 02 68 03 15 01 00 00 00 00 02 ff 24 15 01 00 00 00 00 02 fb 01 15 01 00 00 00 00 02 00 1c 15 01 00 00 00 00 02 01 0b 15 01 00 00 00 00 02 02 0c 15 01 00 00 00 00 02 03 01 15 01 00 00 00 00 02 04 0f 15 01 00 00 00 00 02 05 10 15 01 00 00 00 00 02 06 10 15 01 00 00 00 00 02 07 10 15 01 00 00 00 00 02 08 89 15 01 00 00 00 00 02 09 8a 15 01 00 00 00 00 02 0a 13 15 01 00 00 00 00 02 0b 13 15 01 00 00 00 00 02 0c 15 15 01 00 00 00 00 02 0d 15 15 01 00 00 00 00 02 0e 17 15 01 00 00 00 00 02 0f 17 15 01 00 00 00 00 02 10 1c 15 01 00 00 00 00 02 11 0b 15 01 00 00 00 00 02 12 0c 15 01 00 00 00 00 02 13 01 15 01 00 00 00 00 02 14 0f 15 01 00 00 00 00 02 15 10 15 01 00 00 00 00 02 16 10 15 01 00 00 00 00 02 17 10 15 01 00 00 00 00 02 18 89 15 01 00 00 00 00 02 19 8a 15 01 00 00 00 00 02 1a 13 15 01 00 00 00 00 02 1b 13 15 01 00 00 00 00 02 1c 15 15 01 00 00 00 00 02 1d 15 15 01 00 00 00 00 02 1e 17 15 01 00 00 00 00 02 1f 17 15 01 00 00 00 00 02 20 40 15 01 00 00 00 00 02 21 01 15 01 00 00 00 00 02 22 00 15 01 00 00 00 00 02 23 40 15 01 00 00 00 00 02 24 40 15 01 00 00 00 00 02 25 6d 15 01 00 00 00 00 02 26 40 15 01 00 00 00 00 02 27 40 15 01 00 00 00 00 02 e0 00 15 01 00 00 00 00 02 dc 21 15 01 00 00 00 00 02 dd 22 15 01 00 00 00 00 02 de 07 15 01 00 00 00 00 02 df 07 15 01 00 00 00 00 02 e3 6d 15 01 00 00 00 00 02 e1 07 15 01 00 00 00 00 02 e2 07 15 01 00 00 00 00 02 29 d8 15 01 00 00 00 00 02 2a 2a 15 01 00 00 00 00 02 4b 03 15 01 00 00 00 00 02 4c 11 15 01 00 00 00 00 02 4d 10 15 01 00 00 00 00 02 4e 01 15 01 00 00 00 00 02 4f 01 15 01 00 00 00 00 02 50 10 15 01 00 00 00 00 02 51 00 15 01 00 00 00 00 02 52 80 15 01 00 00 00 00 02 53 00 15 01 00 00 00 00 02 56 00 15 01 00 00 00 00 02 54 07 15 01 00 00 00 00 02 58 07 15 01 00 00 00 00 02 55 25 15 01 00 00 00 00 02 5b 43 15 01 00 00 00 00 02 5c 00 15 01 00 00 00 00 02 5f 73 15 01 00 00 00 00 02 60 73 15 01 00 00 00 00 02 63 22 15 01 00 00 00 00 02 64 00 15 01 00 00 00 00 02 67 08 15 01 00 00 00 00 02 68 04 15 01 00 00 00 00 02 72 02 15 01 00 00 00 00 02 7a 80 15 01 00 00 00 00 02 7b 91 15 01 00 00 00 00 02 7c d8 15 01 00 00 00 00 02 7d 60 15 01 00 00 00 00 02 7f 15 15 01 00 00 00 00 02 75 15 15 01 00 00 00 00 02 b3 c0 15 01 00 00 00 00 02 b4 00 15 01 00 00 00 00 02 b5 00 15 01 00 00 00 00 02 78 00 15 01 00 00 00 00 02 79 00 15 01 00 00 00 00 02 80 00 15 01 00 00 00 00 02 83 00 15 01 00 00 00 00 02 93 0a 15 01 00 00 00 00 02 94 0a 15 01 00 00 00 00 02 8a 00 15 01 00 00 00 00 02 9b ff 15 01 00 00 00 00 02 9d b0 15 01 00 00 00 00 02 9f 63 15 01 00 00 00 00 02 98 10 15 01 00 00 00 00 02 ec 00 15 01 00 00 00 00 02 ff 10 39 01 00 00 00 00 04 3b 03 0a 0a 15 01 00 00 00 00 02 35 00 15 01 00 00 00 00 02 e5 01 15 01 00 00 00 00 02 bb 10 15 01 00 00 00 00 02 fb 01 05 01 00 00 f0 00 01 00];
			qcom,mdss-dsi-h-sync-pulse = <0x00>;
			qcom,mdss-dsi-v-bottom-border = <0x00>;
			qcom,mdss-dsi-v-top-border = <0x00>;
			qcom,mdss-dsi-h-right-border = <0x00>;
			qcom,mdss-dsi-h-left-border = <0x00>;
			qcom,mdss-dsi-v-pulse-width = <0x01>;
			qcom,mdss-dsi-v-front-porch = <0x08>;
			qcom,mdss-dsi-v-back-porch = <0x07>;
			qcom,mdss-dsi-h-sync-skew = <0x00>;
			qcom,mdss-dsi-h-pulse-width = <0x10>;
			qcom,mdss-dsi-h-back-porch = <0x20>;
			qcom,mdss-dsi-h-front-porch = <0x64>;
			qcom,mdss-dsi-panel-height = <0xa00>;
			qcom,mdss-dsi-panel-width = <0x2d0>;
			qcom,mdss-dsi-panel-framerate = <0x78>;
			cell-index = <0x0b>;
		};

		timing@11 {
			qcom,default-topology-index = <0x00>;
			qcom,display-topology = <0x02 0x02 0x02>;
			qcom,mdss-dsi-panel-phy-timings = [00 1a 07 06 16 21 07 07 07 02 04 00 17 0c];
			qcom,mdss-dsc-block-prediction-enable;
			qcom,mdss-dsc-bit-per-pixel = <0x08>;
			qcom,mdss-dsc-bit-per-component = <0x0a>;
			qcom,mdss-dsc-slice-per-pkt = <0x02>;
			qcom,mdss-dsc-slice-width = <0x4ec>;
			qcom,mdss-dsc-slice-height = <0x438>;
			qcom,compression-mode = "dsc";
			qcom,mdss-dsi-off-command-state = "dsi_hs_mode";
			qcom,mdss-dsi-off-command = [05 01 00 00 78 00 02 28 00 05 01 00 00 78 00 02 10 00];
			qcom,mdss-dsi-on-command-state = "dsi_lp_mode";
			qcom,mdss-dsi-on-command = [39 01 00 00 00 00 11 91 09 20 00 20 02 00 03 1c 04 21 00 0f 03 19 01 97 39 01 00 00 00 00 03 92 10 f0 15 01 00 00 00 00 02 90 03 15 01 00 00 00 00 02 03 01 39 01 00 00 00 00 06 f0 55 aa 52 08 04 15 01 00 00 00 00 02 c0 03 39 01 00 00 00 00 06 f0 55 aa 52 08 07 15 01 00 00 00 00 02 ef 01 39 01 00 00 00 00 06 f0 55 aa 52 08 00 15 01 00 00 00 00 02 b4 01 15 01 00 00 00 00 02 35 00 39 01 00 00 00 00 06 f0 55 aa 52 08 01 39 01 00 00 00 00 05 ff aa 55 a5 80 15 01 00 00 00 00 02 6f 01 15 01 00 00 00 00 02 f3 10 39 01 00 00 00 00 05 ff aa 55 a5 00 05 01 00 00 f0 00 01 00];
			qcom,mdss-dsi-panel-framerate = <0x3c>;
			qcom,mdss-dsi-h-sync-pulse = <0x00>;
			qcom,mdss-dsi-v-pulse-width = <0x01>;
			qcom,mdss-dsi-v-front-porch = <0x08>;
			qcom,mdss-dsi-v-back-porch = <0x07>;
			qcom,mdss-dsi-h-sync-skew = <0x00>;
			qcom,mdss-dsi-h-pulse-width = <0x04>;
			qcom,mdss-dsi-h-back-porch = <0x64>;
			qcom,mdss-dsi-h-front-porch = <0x1e>;
			qcom,mdss-dsi-panel-height = <0x870>;
			qcom,mdss-dsi-panel-width = <0x9d8>;
			cell-index = <0x0c>;
		};

		timing@12 {
			qcom,default-topology-index = <0x00>;
			qcom,display-topology = <0x02 0x02 0x02>;
			qcom,mdss-dsi-panel-phy-timings = [03 07 00 01 0d 1a 01 01 01 02 04 00 07 06];
			qcom,mdss-dsc-block-prediction-enable;
			qcom,mdss-dsc-bit-per-pixel = <0x08>;
			qcom,mdss-dsc-bit-per-component = <0x0a>;
			qcom,mdss-dsc-slice-per-pkt = <0x01>;
			qcom,mdss-dsc-slice-width = <0x168>;
			qcom,mdss-dsc-slice-height = <0x20>;
			qcom,compression-mode = "dsc";
			qcom,mdss-dsi-off-command-state = "dsi_hs_mode";
			qcom,mdss-dsi-off-command = [05 01 00 00 78 00 02 28 00 05 01 00 00 78 00 02 10 00];
			qcom,mdss-dsi-on-command-state = "dsi_lp_mode";
			qcom,mdss-dsi-on-command = [39 01 00 00 00 00 11 91 09 20 00 20 02 00 03 1c 04 21 00 0f 03 19 01 97 39 01 00 00 00 00 03 92 10 f0 15 01 00 00 00 00 02 90 03 15 01 00 00 00 00 02 03 01 39 01 00 00 00 00 06 f0 55 aa 52 08 04 15 01 00 00 00 00 02 c0 03 39 01 00 00 00 00 06 f0 55 aa 52 08 07 15 01 00 00 00 00 02 ef 01 39 01 00 00 00 00 06 f0 55 aa 52 08 00 15 01 00 00 00 00 02 b4 01 15 01 00 00 00 00 02 35 00 39 01 00 00 00 00 06 f0 55 aa 52 08 01 39 01 00 00 00 00 05 ff aa 55 a5 80 15 01 00 00 00 00 02 6f 01 15 01 00 00 00 00 02 f3 10 39 01 00 00 00 00 05 ff aa 55 a5 00 05 01 00 00 f0 00 01 00];
			qcom,mdss-dsi-panel-framerate = <0x1e>;
			qcom,mdss-dsi-h-sync-pulse = <0x00>;
			qcom,mdss-dsi-v-pulse-width = <0x01>;
			qcom,mdss-dsi-v-front-porch = <0x08>;
			qcom,mdss-dsi-v-back-porch = <0x07>;
			qcom,mdss-dsi-h-sync-skew = <0x00>;
			qcom,mdss-dsi-h-pulse-width = <0x04>;
			qcom,mdss-dsi-h-back-porch = <0x64>;
			qcom,mdss-dsi-h-front-porch = <0x1e>;
			qcom,mdss-dsi-panel-height = <0x500>;
			qcom,mdss-dsi-panel-width = <0x168>;
			cell-index = <0x0d>;
		};

		timing@13 {
			qcom,default-topology-index = <0x00>;
			qcom,display-topology = <0x02 0x02 0x02>;
			qcom,mdss-dsi-panel-phy-timings = [01 09 01 01 0e 1b 01 01 02 02 04 00 08 06];
			qcom,mdss-dsc-block-prediction-enable;
			qcom,mdss-dsc-bit-per-pixel = <0x08>;
			qcom,mdss-dsc-bit-per-component = <0x0a>;
			qcom,mdss-dsc-slice-per-pkt = <0x01>;
			qcom,mdss-dsc-slice-width = <0x168>;
			qcom,mdss-dsc-slice-height = <0x20>;
			qcom,compression-mode = "dsc";
			qcom,mdss-dsi-off-command-state = "dsi_hs_mode";
			qcom,mdss-dsi-off-command = [05 01 00 00 78 00 02 28 00 05 01 00 00 78 00 02 10 00];
			qcom,mdss-dsi-on-command-state = "dsi_lp_mode";
			qcom,mdss-dsi-on-command = [39 01 00 00 00 00 11 91 09 20 00 20 02 00 03 1c 04 21 00 0f 03 19 01 97 39 01 00 00 00 00 03 92 10 f0 15 01 00 00 00 00 02 90 03 15 01 00 00 00 00 02 03 01 39 01 00 00 00 00 06 f0 55 aa 52 08 04 15 01 00 00 00 00 02 c0 03 39 01 00 00 00 00 06 f0 55 aa 52 08 07 15 01 00 00 00 00 02 ef 01 39 01 00 00 00 00 06 f0 55 aa 52 08 00 15 01 00 00 00 00 02 b4 01 15 01 00 00 00 00 02 35 00 39 01 00 00 00 00 06 f0 55 aa 52 08 01 39 01 00 00 00 00 05 ff aa 55 a5 80 15 01 00 00 00 00 02 6f 01 15 01 00 00 00 00 02 f3 10 39 01 00 00 00 00 05 ff aa 55 a5 00 05 01 00 00 f0 00 01 00];
			qcom,mdss-dsi-panel-framerate = <0x3c>;
			qcom,mdss-dsi-h-sync-pulse = <0x00>;
			qcom,mdss-dsi-v-pulse-width = <0x01>;
			qcom,mdss-dsi-v-front-porch = <0x08>;
			qcom,mdss-dsi-v-back-porch = <0x07>;
			qcom,mdss-dsi-h-sync-skew = <0x00>;
			qcom,mdss-dsi-h-pulse-width = <0x04>;
			qcom,mdss-dsi-h-back-porch = <0x64>;
			qcom,mdss-dsi-h-front-porch = <0x1e>;
			qcom,mdss-dsi-panel-height = <0x500>;
			qcom,mdss-dsi-panel-width = <0x168>;
			cell-index = <0x0e>;
		};

		timing@14 {
			qcom,default-topology-index = <0x00>;
			qcom,display-topology = <0x02 0x02 0x02>;
			qcom,mdss-dsi-panel-phy-timings = [00 0a 02 02 0f 1c 02 02 02 02 04 00 0a 07];
			qcom,mdss-dsc-block-prediction-enable;
			qcom,mdss-dsc-bit-per-pixel = <0x08>;
			qcom,mdss-dsc-bit-per-component = <0x0a>;
			qcom,mdss-dsc-slice-per-pkt = <0x01>;
			qcom,mdss-dsc-slice-width = <0x168>;
			qcom,mdss-dsc-slice-height = <0x20>;
			qcom,compression-mode = "dsc";
			qcom,mdss-dsi-off-command-state = "dsi_hs_mode";
			qcom,mdss-dsi-off-command = [05 01 00 00 78 00 02 28 00 05 01 00 00 78 00 02 10 00];
			qcom,mdss-dsi-on-command-state = "dsi_lp_mode";
			qcom,mdss-dsi-on-command = [39 01 00 00 00 00 11 91 09 20 00 20 02 00 03 1c 04 21 00 0f 03 19 01 97 39 01 00 00 00 00 03 92 10 f0 15 01 00 00 00 00 02 90 03 15 01 00 00 00 00 02 03 01 39 01 00 00 00 00 06 f0 55 aa 52 08 04 15 01 00 00 00 00 02 c0 03 39 01 00 00 00 00 06 f0 55 aa 52 08 07 15 01 00 00 00 00 02 ef 01 39 01 00 00 00 00 06 f0 55 aa 52 08 00 15 01 00 00 00 00 02 b4 01 15 01 00 00 00 00 02 35 00 39 01 00 00 00 00 06 f0 55 aa 52 08 01 39 01 00 00 00 00 05 ff aa 55 a5 80 15 01 00 00 00 00 02 6f 01 15 01 00 00 00 00 02 f3 10 39 01 00 00 00 00 05 ff aa 55 a5 00 05 01 00 00 f0 00 01 00];
			qcom,mdss-dsi-panel-framerate = <0x5a>;
			qcom,mdss-dsi-h-sync-pulse = <0x00>;
			qcom,mdss-dsi-v-pulse-width = <0x01>;
			qcom,mdss-dsi-v-front-porch = <0x08>;
			qcom,mdss-dsi-v-back-porch = <0x07>;
			qcom,mdss-dsi-h-sync-skew = <0x00>;
			qcom,mdss-dsi-h-pulse-width = <0x04>;
			qcom,mdss-dsi-h-back-porch = <0x64>;
			qcom,mdss-dsi-h-front-porch = <0x1e>;
			qcom,mdss-dsi-panel-height = <0x500>;
			qcom,mdss-dsi-panel-width = <0x168>;
			cell-index = <0x0f>;
		};

		timing@15 {
			qcom,default-topology-index = <0x00>;
			qcom,display-topology = <0x02 0x02 0x02>;
			qcom,mdss-dsi-panel-phy-timings = [00 0b 02 02 0f 0f 03 03 02 02 04 00 0a 08];
			qcom,mdss-dsc-block-prediction-enable;
			qcom,mdss-dsc-bit-per-pixel = <0x08>;
			qcom,mdss-dsc-bit-per-component = <0x0a>;
			qcom,mdss-dsc-slice-per-pkt = <0x01>;
			qcom,mdss-dsc-slice-width = <0x168>;
			qcom,mdss-dsc-slice-height = <0x20>;
			qcom,compression-mode = "dsc";
			qcom,mdss-dsi-off-command-state = "dsi_hs_mode";
			qcom,mdss-dsi-off-command = [05 01 00 00 78 00 02 28 00 05 01 00 00 78 00 02 10 00];
			qcom,mdss-dsi-on-command-state = "dsi_lp_mode";
			qcom,mdss-dsi-on-command = [39 01 00 00 00 00 11 91 09 20 00 20 02 00 03 1c 04 21 00 0f 03 19 01 97 39 01 00 00 00 00 03 92 10 f0 15 01 00 00 00 00 02 90 03 15 01 00 00 00 00 02 03 01 39 01 00 00 00 00 06 f0 55 aa 52 08 04 15 01 00 00 00 00 02 c0 03 39 01 00 00 00 00 06 f0 55 aa 52 08 07 15 01 00 00 00 00 02 ef 01 39 01 00 00 00 00 06 f0 55 aa 52 08 00 15 01 00 00 00 00 02 b4 01 15 01 00 00 00 00 02 35 00 39 01 00 00 00 00 06 f0 55 aa 52 08 01 39 01 00 00 00 00 05 ff aa 55 a5 80 15 01 00 00 00 00 02 6f 01 15 01 00 00 00 00 02 f3 10 39 01 00 00 00 00 05 ff aa 55 a5 00 05 01 00 00 f0 00 01 00];
			qcom,mdss-dsi-panel-framerate = <0x78>;
			qcom,mdss-dsi-h-sync-pulse = <0x00>;
			qcom,mdss-dsi-v-pulse-width = <0x01>;
			qcom,mdss-dsi-v-front-porch = <0x08>;
			qcom,mdss-dsi-v-back-porch = <0x07>;
			qcom,mdss-dsi-h-sync-skew = <0x00>;
			qcom,mdss-dsi-h-pulse-width = <0x04>;
			qcom,mdss-dsi-h-back-porch = <0x64>;
			qcom,mdss-dsi-h-front-porch = <0x1e>;
			qcom,mdss-dsi-panel-height = <0x500>;
			qcom,mdss-dsi-panel-width = <0x168>;
			cell-index = <0x10>;
		};

		timing@16 {
			qcom,default-topology-index = <0x00>;
			qcom,display-topology = <0x02 0x02 0x02>;
			qcom,mdss-dsi-panel-phy-timings = [00 13 05 04 13 12 05 05 06 02 04 00 12 0a];
			qcom,mdss-dsc-block-prediction-enable;
			qcom,mdss-dsc-bit-per-pixel = <0x08>;
			qcom,mdss-dsc-bit-per-component = <0x0a>;
			qcom,mdss-dsc-slice-per-pkt = <0x01>;
			qcom,mdss-dsc-slice-width = <0x21c>;
			qcom,mdss-dsc-slice-height = <0x20>;
			qcom,compression-mode = "dsc";
			qcom,mdss-dsi-off-command-state = "dsi_hs_mode";
			qcom,mdss-dsi-off-command = [05 01 00 00 78 00 02 28 00 05 01 00 00 78 00 02 10 00];
			qcom,mdss-dsi-on-command-state = "dsi_lp_mode";
			qcom,mdss-dsi-on-command = [39 01 00 00 00 00 11 91 09 20 00 20 02 00 03 1c 04 21 00 0f 03 19 01 97 39 01 00 00 00 00 03 92 10 f0 15 01 00 00 00 00 02 90 03 15 01 00 00 00 00 02 03 01 39 01 00 00 00 00 06 f0 55 aa 52 08 04 15 01 00 00 00 00 02 c0 03 39 01 00 00 00 00 06 f0 55 aa 52 08 07 15 01 00 00 00 00 02 ef 01 39 01 00 00 00 00 06 f0 55 aa 52 08 00 15 01 00 00 00 00 02 b4 01 15 01 00 00 00 00 02 35 00 39 01 00 00 00 00 06 f0 55 aa 52 08 01 39 01 00 00 00 00 05 ff aa 55 a5 80 15 01 00 00 00 00 02 6f 01 15 01 00 00 00 00 02 f3 10 39 01 00 00 00 00 05 ff aa 55 a5 00 05 01 00 00 f0 00 01 00];
			qcom,mdss-dsi-panel-framerate = <0x90>;
			qcom,mdss-dsi-h-sync-pulse = <0x00>;
			qcom,mdss-dsi-v-pulse-width = <0x01>;
			qcom,mdss-dsi-v-front-porch = <0x08>;
			qcom,mdss-dsi-v-back-porch = <0x07>;
			qcom,mdss-dsi-h-sync-skew = <0x00>;
			qcom,mdss-dsi-h-pulse-width = <0x04>;
			qcom,mdss-dsi-h-back-porch = <0x64>;
			qcom,mdss-dsi-h-front-porch = <0x1e>;
			qcom,mdss-dsi-panel-height = <0x780>;
			qcom,mdss-dsi-panel-width = <0x21c>;
			cell-index = <0x11>;
		};

		timing@17 {
			qcom,default-topology-index = <0x00>;
			qcom,display-topology = <0x02 0x02 0x02>;
			qcom,mdss-dsi-panel-phy-timings = [00 1d 07 07 17 16 07 07 08 02 04 00 19 0c];
			qcom,mdss-dsc-block-prediction-enable;
			qcom,mdss-dsc-bit-per-pixel = <0x08>;
			qcom,mdss-dsc-bit-per-component = <0x0a>;
			qcom,mdss-dsc-slice-per-pkt = <0x01>;
			qcom,mdss-dsc-slice-width = <0x2d0>;
			qcom,mdss-dsc-slice-height = <0x10>;
			qcom,compression-mode = "dsc";
			qcom,mdss-dsi-off-command-state = "dsi_hs_mode";
			qcom,mdss-dsi-off-command = [05 01 00 00 78 00 02 28 00 05 01 00 00 78 00 02 10 00];
			qcom,mdss-dsi-on-command-state = "dsi_lp_mode";
			qcom,mdss-dsi-on-command = [39 01 00 00 00 00 11 91 09 20 00 20 02 00 03 1c 04 21 00 0f 03 19 01 97 39 01 00 00 00 00 03 92 10 f0 15 01 00 00 00 00 02 90 03 15 01 00 00 00 00 02 03 01 39 01 00 00 00 00 06 f0 55 aa 52 08 04 15 01 00 00 00 00 02 c0 03 39 01 00 00 00 00 06 f0 55 aa 52 08 07 15 01 00 00 00 00 02 ef 01 39 01 00 00 00 00 06 f0 55 aa 52 08 00 15 01 00 00 00 00 02 b4 01 15 01 00 00 00 00 02 35 00 39 01 00 00 00 00 06 f0 55 aa 52 08 01 39 01 00 00 00 00 05 ff aa 55 a5 80 15 01 00 00 00 00 02 6f 01 15 01 00 00 00 00 02 f3 10 39 01 00 00 00 00 05 ff aa 55 a5 00 05 01 00 00 f0 00 01 00];
			qcom,mdss-dsi-panel-framerate = <0x90>;
			qcom,mdss-dsi-h-sync-pulse = <0x00>;
			qcom,mdss-dsi-v-pulse-width = <0x01>;
			qcom,mdss-dsi-v-front-porch = <0x08>;
			qcom,mdss-dsi-v-back-porch = <0x07>;
			qcom,mdss-dsi-h-sync-skew = <0x00>;
			qcom,mdss-dsi-h-pulse-width = <0x04>;
			qcom,mdss-dsi-h-back-porch = <0x64>;
			qcom,mdss-dsi-h-front-porch = <0x1e>;
			qcom,mdss-dsi-panel-height = <0xa00>;
			qcom,mdss-dsi-panel-width = <0x2d0>;
			cell-index = <0x12>;
		};
	};
};
